# MSS_CTRL_MSS_CTRL_50D00000h register map
Vendor: Texas Instruments
Registers are 32-bit, read-write, reset values left out (the file's numbers can be read two ways) unless marked. A register's access mark holds for its fields unless they carry their own. Offsets are as the file gives them; [hi:lo] are bit positions; {n}, {i} and the like mark numbered series; 'fields as' and 'values as' point back to an identical list.

## MSS_CTRL (part 2 of 6)
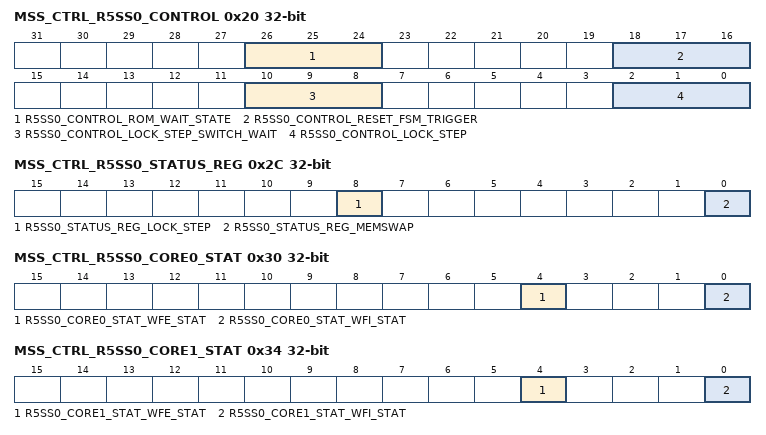
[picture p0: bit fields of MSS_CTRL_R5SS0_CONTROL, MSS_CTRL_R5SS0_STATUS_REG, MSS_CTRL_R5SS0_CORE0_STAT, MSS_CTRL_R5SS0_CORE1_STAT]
0x20 MSS_CTRL_R5SS0_CONTROL
  [26:24] R5SS0_CONTROL_ROM_WAIT_STATE — Writing 3'b111 enables a single cycle wait state with respect to CR5A_clk for rom access.This needs to be set when R5 clock is at 400MHZ and Interconnect-clk is at 200MHZ. [because it is a timing issue in this scenario]
  [18:16] R5SS0_CONTROL_RESET_FSM_TRIGGER — Write pulse bit field:Writing 3'b111 will trigger the reset FSM. Reset FSM ensures reset to R5SS and inturn ensures the latching of lock_step and also mem_swap bit
  [10:8] R5SS0_CONTROL_LOCK_STEP_SWITCH_WAIT — Writing 3'b111 ensures switch happens only after R5SS reset. Orelse it will be a immediate switch.
  [2:0] R5SS0_CONTROL_LOCK_STEP — Writing 3'b000 ensures R5 to be in Dual-Core mode. Note: The change happens after the R5SS reset assertion if corresponding R5SS_CONTROL_LOCK_STEP_SWITCH_WAIT is set. Or else the switiching to Dual-core happens on the fly.
0x24 MSS_CTRL_R5SS0_CORE0_HALT
  [2:0] R5SS0_CORE0_HALT_HALT — Writing 3'b000 will unhalt CR5A. This register should be written only once.
0x28 MSS_CTRL_R5SS0_CORE1_HALT
  [2:0] R5SS0_CORE1_HALT_HALT — Writing 3'b000 will unhalt for CR5B. This register should be written only once.
0x2C MSS_CTRL_R5SS0_STATUS_REG ro
  [8] R5SS0_STATUS_REG_LOCK_STEP — Reading1:confirms R5SS is in lockstep mode. Reading0:confirms R5SS is in Dual-core mode.
  [0] R5SS0_STATUS_REG_MEMSWAP — Reading1:confirms ROM is Eclipsed from with RAM for R5.
0x30 MSS_CTRL_R5SS0_CORE0_STAT ro
  [4] R5SS0_CORE0_STAT_WFE_STAT — WFE Status
  [0] R5SS0_CORE0_STAT_WFI_STAT — WFI Status
0x34 MSS_CTRL_R5SS0_CORE1_STAT ro
  [4] R5SS0_CORE1_STAT_WFE_STAT — WFE Status
  [0] R5SS0_CORE1_STAT_WFI_STAT — WFI Status
0x38 MSS_CTRL_R5SS0_FORCE_WFI
  [2:0] R5SS0_FORCE_WFI_CR5_WFI_OVERIDE — Writing 3'b111 will force the wfi signals of R5SS to 1
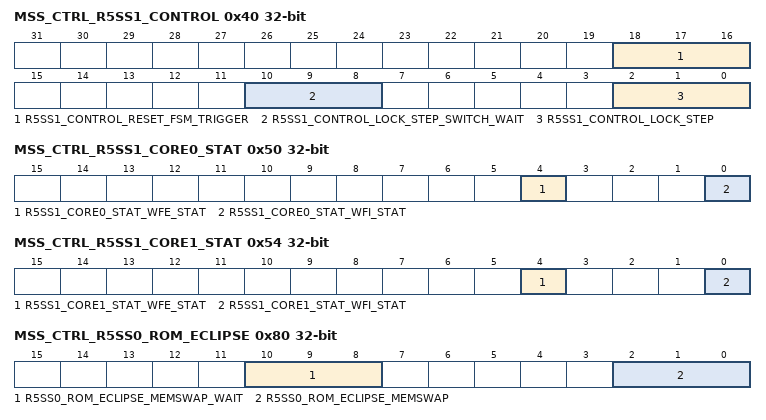
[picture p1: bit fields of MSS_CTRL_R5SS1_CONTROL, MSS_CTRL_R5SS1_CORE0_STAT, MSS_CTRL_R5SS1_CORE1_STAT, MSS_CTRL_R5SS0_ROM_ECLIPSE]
0x40 MSS_CTRL_R5SS1_CONTROL
  [18:16] R5SS1_CONTROL_RESET_FSM_TRIGGER — Write pulse bit field:Writing 3'b111 will trigger the reset FSM. Reset FSM ensures reset to R5SS and inturn ensures the latching of lock_step and also mem_swap bit
  [10:8] R5SS1_CONTROL_LOCK_STEP_SWITCH_WAIT — Writing 3'b111 ensures switch happens only after R5SS reset. Orelse it will be a immediate switch.
  [2:0] R5SS1_CONTROL_LOCK_STEP — Writing 3'b000 ensures R5 to be in Dual-Core mode. Note: The change happens after the R5SS reset assertion if corresponding R5SS_CONTROL_LOCK_STEP_SWITCH_WAIT is set. Or else the switiching to Dual-core happens on the fly.
0x44 MSS_CTRL_R5SS1_CORE0_HALT
  [2:0] R5SS1_CORE0_HALT_HALT — Writing 3'b000 will unhalt CR5A. This register should be written only once.
0x48 MSS_CTRL_R5SS1_CORE1_HALT
  [2:0] R5SS1_CORE1_HALT_HALT — Writing 3'b000 will unhalt for CR5B. This register should be written only once.
0x4C MSS_CTRL_R5SS1_STATUS_REG ro
  [8] R5SS1_STATUS_REG_LOCK_STEP — Reading1:confirms R5SS is in lockstep mode. Reading0:confirms R5SS is in Dual-core mode.
0x50 MSS_CTRL_R5SS1_CORE0_STAT ro
  [4] R5SS1_CORE0_STAT_WFE_STAT — WFE Status
  [0] R5SS1_CORE0_STAT_WFI_STAT — WFI Status
0x54 MSS_CTRL_R5SS1_CORE1_STAT ro
  [4] R5SS1_CORE1_STAT_WFE_STAT — WFE Status
  [0] R5SS1_CORE1_STAT_WFI_STAT — WFI Status
0x58 MSS_CTRL_R5SS1_FORCE_WFI
  [2:0] R5SS1_FORCE_WFI_CR5_WFI_OVERIDE — Writing 3'b111 will force the wfi signals of R5SS to 1
0x80 MSS_CTRL_R5SS0_ROM_ECLIPSE
  [10:8] R5SS0_ROM_ECLIPSE_MEMSWAP_WAIT — Writing 3'b111 ensures ROM-Eclipsing happens only after R5SS reset. Or else it will be a immediate change.
  [2:0] R5SS0_ROM_ECLIPSE_MEMSWAP — Writing 3'b111 ensures eclipsing of CR5A_ROM immediately if memswap_wait is not set. If memswap_wait is set then ROM is eclipsed after R5SS reset assertion.
0x200 MSS_CTRL_R5SS0_ATCM_MEM_INIT
  [0] R5SS0_ATCM_MEM_INIT_MEM_INIT — Write_pulse bit field:Writing 1'b1 will start initializing the ATCM banks of CR5A/B. Value in each row is initialized to 0x0C_0000_0000
0x204 MSS_CTRL_R5SS0_ATCM_MEM_INIT_DONE
  [0] R5SS0_ATCM_MEM_INIT_DONE_MEM_INIT_DONE — This field will be high once initialization of ATCM banks is finished. Writing '1' would clear the bit.
0x208 MSS_CTRL_R5SS0_ATCM_MEM_INIT_STATUS ro
  [0] R5SS0_ATCM_MEM_INIT_STATUS_MEM_STATUS — 1'b0: No initialization is happening for ATCM banks of CR5A/B1'b1: Initialization is in progress for ATCM banks of CR5A/B
0x210 MSS_CTRL_R5SS0_BTCM_MEM_INIT
  [0] R5SS0_BTCM_MEM_INIT_MEM_INIT — Write_pulse bit field:Writing 1'b1 will start initializing the B0/1TCM banks of CR5A/B
0x214 MSS_CTRL_R5SS0_BTCM_MEM_INIT_DONE
  [0] R5SS0_BTCM_MEM_INIT_DONE_MEM_INIT_DONE — This field will be high once initialization of B0/1TCM banks is finished. Writing '1' would clear the bit.
0x218 MSS_CTRL_R5SS0_BTCM_MEM_INIT_STATUS ro
  [0] R5SS0_BTCM_MEM_INIT_STATUS_MEM_STATUS — 1'b0: No initialization is happening for B0/1TCM banks of CR5A/B1'b1: Initialization is in progress for B0/1TCM banks of CR5A/B
0x220 MSS_CTRL_R5SS1_ATCM_MEM_INIT
  [0] R5SS1_ATCM_MEM_INIT_MEM_INIT — Write_pulse bit field:Writing 1'b1 will start initializing the ATCM banks of CR5A/B. Value in each row is initialized to 0x0C_0000_0000
0x224 MSS_CTRL_R5SS1_ATCM_MEM_INIT_DONE
  [0] R5SS1_ATCM_MEM_INIT_DONE_MEM_INIT_DONE — This field will be high once initialization of ATCM banks is finished. Writing '1' would clear the bit.
0x228 MSS_CTRL_R5SS1_ATCM_MEM_INIT_STATUS ro
  [0] R5SS1_ATCM_MEM_INIT_STATUS_MEM_STATUS — 1'b0: No initialization is happening for ATCM banks of CR5A/B1'b1: Initialization is in progress for ATCM banks of CR5A/B
0x230 MSS_CTRL_R5SS1_BTCM_MEM_INIT
  [0] R5SS1_BTCM_MEM_INIT_MEM_INIT — Write_pulse bit field:Writing 1'b1 will start initializing the B0/1TCM banks of CR5A/B
0x234 MSS_CTRL_R5SS1_BTCM_MEM_INIT_DONE
  [0] R5SS1_BTCM_MEM_INIT_DONE_MEM_INIT_DONE — This field will be high once initialization of B0/1TCM banks is finished. Writing '1' would clear the bit.
0x238 MSS_CTRL_R5SS1_BTCM_MEM_INIT_STATUS ro
  [0] R5SS1_BTCM_MEM_INIT_STATUS_MEM_STATUS — 1'b0: No initialization is happening for B0/1TCM banks of CR5A/B1'b1: Initialization is in progress for B0/1TCM banks of CR5A/B
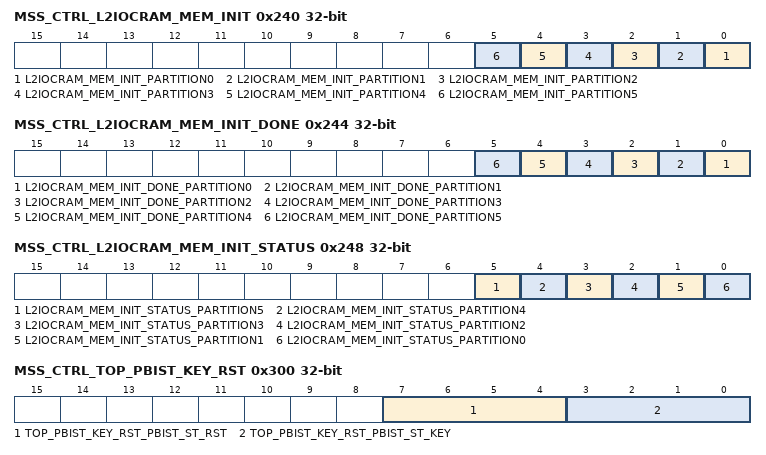
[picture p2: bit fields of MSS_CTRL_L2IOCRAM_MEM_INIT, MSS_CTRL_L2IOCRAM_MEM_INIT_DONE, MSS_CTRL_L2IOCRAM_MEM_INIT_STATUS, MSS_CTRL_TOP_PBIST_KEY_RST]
0x240 MSS_CTRL_L2IOCRAM_MEM_INIT
  [n] L2IOCRAM_MEM_INIT_PARTITION{n} (n=0..5) — Write_pulse bit field:Writing 1'b1 will start initializing the L2 Bank{n}. Value in each row is initialized to 0x0
0x244 MSS_CTRL_L2IOCRAM_MEM_INIT_DONE
  [n] L2IOCRAM_MEM_INIT_DONE_PARTITION{n} (n=0..5) — This field will be high once intialization of L2 bank{n} is finished. Writing '1' would clear the bit
0x248 MSS_CTRL_L2IOCRAM_MEM_INIT_STATUS ro
  [5] L2IOCRAM_MEM_INIT_STATUS_PARTITION5 — 1'b0: No initialization is happening for L2 bank51'b1: Initialization is in progress for L2 bank5
  [4] L2IOCRAM_MEM_INIT_STATUS_PARTITION4 — 1'b0: No initialization is happening for L2 bank41'b1: Initialization is in progress for L2 bank4
  [3] L2IOCRAM_MEM_INIT_STATUS_PARTITION3 — 1'b0: No initialization is happening for L2 bank31'b1: Initialization is in progress for L2 bank3
  [2] L2IOCRAM_MEM_INIT_STATUS_PARTITION2 — 1'b0: No initialization is happening for L2 bank2 1'b1: Initialization is in progress for L2 bank2
  [1] L2IOCRAM_MEM_INIT_STATUS_PARTITION1 — 1'b0: No initialization is happening for L2 bank11'b1: Initialization is in progress for L2 bank1
  [0] L2IOCRAM_MEM_INIT_STATUS_PARTITION0 — 1'b0: No initialization is happening for L2 bank0 1'b1: Initialization is in progress for L2 bank0
0x250 MSS_CTRL_MAILBOXRAM_MEM_INIT
  [0] MAILBOXRAM_MEM_INIT_MEM0_INIT — Write_pulse bit field:Writing 1'b1 will start initializing the MSS_MBOX. Value in each row is initialized to 0x0
0x254 MSS_CTRL_MAILBOXRAM_MEM_INIT_DONE
  [0] MAILBOXRAM_MEM_INIT_DONE_MEM0_DONE — This field will be high once intialization of MSS_MBOX is finished. Writing '1' would clear the bit
0x258 MSS_CTRL_MAILBOXRAM_MEM_INIT_STATUS ro
  [0] MAILBOXRAM_MEM_INIT_STATUS_MEM0_STATUS — 1'b0: No initialization is happening for MSS_MBOX 1'b1: Initialization is in progress for MSS_MBOX
0x260 MSS_CTRL_TPCC_MEM_INIT
  [0] TPCC_MEM_INIT_TPCC_A_MEMINIT_START — Write_pulse bit field:Writing 1'b1 will start initializing the MSS_TPCCA
0x264 MSS_CTRL_TPCC_MEM_INIT_DONE
  [0] TPCC_MEM_INIT_DONE_TPCC_A_MEMINIT_DONE — This field will be high once intialization of MSS_TPCCA is finished. Writing '1' would clear the bit
0x268 MSS_CTRL_TPCC_MEMINIT_STATUS ro
  [0] TPCC_MEMINIT_STATUS_TPCC_A_MEMINIT_STATUS — 1'b0: No initialization is happening for MSS_TPCCA1'b1: Initialization is in progress for MSS_TPCCB
0x300 MSS_CTRL_TOP_PBIST_KEY_RST
  [7:4] TOP_PBIST_KEY_RST_PBIST_ST_RST — MSS PBIST controller will be brought out of reset when value is 0xA
  [3:0] TOP_PBIST_KEY_RST_PBIST_ST_KEY — Top PBIST Selftest Key. Valid value is 0x5
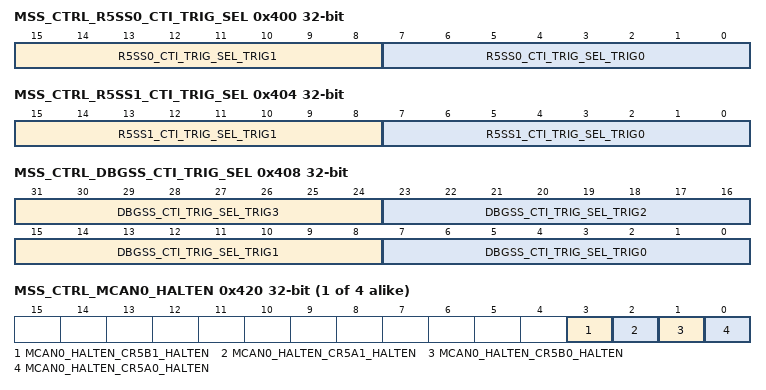
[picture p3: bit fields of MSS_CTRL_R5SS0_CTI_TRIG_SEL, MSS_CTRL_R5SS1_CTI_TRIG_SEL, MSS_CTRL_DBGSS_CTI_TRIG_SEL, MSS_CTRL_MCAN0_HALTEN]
0x400 MSS_CTRL_R5SS0_CTI_TRIG_SEL
  [15:8] R5SS0_CTI_TRIG_SEL_TRIG1 — Used for selecting the trigger source for 1st trigger of MSS_R5SS
  [7:0] R5SS0_CTI_TRIG_SEL_TRIG0 — Used for selecting the trigger source for 0th trigger of MSS_R5SS
0x404 MSS_CTRL_R5SS1_CTI_TRIG_SEL
  [15:8] R5SS1_CTI_TRIG_SEL_TRIG1 — Used for selecting the trigger source for 1st trigger of MSS_R5SS
  [7:0] R5SS1_CTI_TRIG_SEL_TRIG0 — Used for selecting the trigger source for 0th trigger of MSS_R5SS
0x408 MSS_CTRL_DBGSS_CTI_TRIG_SEL
  [31:24] DBGSS_CTI_TRIG_SEL_TRIG3 — Used for selecting the trigger source for 3rd trigger of ONE_MCU_CTI
  [23:16] DBGSS_CTI_TRIG_SEL_TRIG2 — Used for selecting the trigger source for 2nd trigger of ONE_MCU_CTI
  [15:8] DBGSS_CTI_TRIG_SEL_TRIG1 — Used for selecting the trigger source for 1st trigger of ONE_MCU_CTI
  [7:0] DBGSS_CTI_TRIG_SEL_TRIG0 — Used for selecting the trigger source for 0th trigger of ONE_MCU_CTI
{0x420+4i} MSS_CTRL_MCAN{i}_HALTEN (i=0..3)
  [3] MCAN{i}_HALTEN_CR5B1_HALTEN — 1'b0: IP Halt disabled with corresponding CPU halt1'b1: IP Halt enabled with corresponding CPU halt
  [2] MCAN{i}_HALTEN_CR5A1_HALTEN — 1'b0: IP Halt disabled with corresponding CPU halt1'b1: IP Halt enabled with corresponding CPU halt
  [1] MCAN{i}_HALTEN_CR5B0_HALTEN — 1'b0: IP Halt disabled with corresponding CPU halt1'b1: IP Halt enabled with corresponding CPU halt
  [0] MCAN{i}_HALTEN_CR5A0_HALTEN — 1'b0: IP Halt disabled with corresponding CPU halt1'b1: IP Halt enabled with corresponding CPU halt
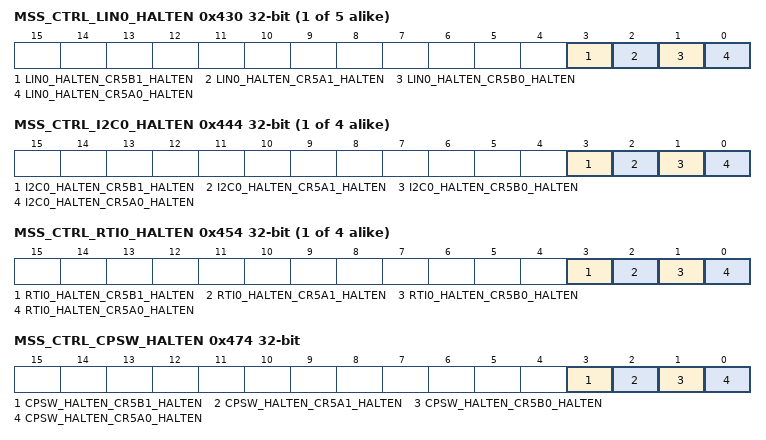
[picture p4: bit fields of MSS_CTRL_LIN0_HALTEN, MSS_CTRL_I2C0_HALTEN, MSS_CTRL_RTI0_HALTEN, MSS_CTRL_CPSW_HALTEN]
{0x430+4i} MSS_CTRL_LIN{i}_HALTEN (i=0..4)
  [3] LIN{i}_HALTEN_CR5B1_HALTEN — 1'b0: IP Halt disabled with corresponding CPU halt1'b1: IP Halt enabled with corresponding CPU halt
  [2] LIN{i}_HALTEN_CR5A1_HALTEN — 1'b0: IP Halt disabled with corresponding CPU halt1'b1: IP Halt enabled with corresponding CPU halt
  [1] LIN{i}_HALTEN_CR5B0_HALTEN — 1'b0: IP Halt disabled with corresponding CPU halt1'b1: IP Halt enabled with corresponding CPU halt
  [0] LIN{i}_HALTEN_CR5A0_HALTEN — 1'b0: IP Halt disabled with corresponding CPU halt1'b1: IP Halt enabled with corresponding CPU halt
{0x444+4i} MSS_CTRL_I2C{i}_HALTEN (i=0..3)
  [3] I2C{i}_HALTEN_CR5B1_HALTEN — 1'b0: IP Halt disabled with corresponding CPU halt1'b1: IP Halt enabled with corresponding CPU halt
  [2] I2C{i}_HALTEN_CR5A1_HALTEN — 1'b0: IP Halt disabled with corresponding CPU halt1'b1: IP Halt enabled with corresponding CPU halt
  [1] I2C{i}_HALTEN_CR5B0_HALTEN — 1'b0: IP Halt disabled with corresponding CPU halt1'b1: IP Halt enabled with corresponding CPU halt
  [0] I2C{i}_HALTEN_CR5A0_HALTEN — 1'b0: IP Halt disabled with corresponding CPU halt1'b1: IP Halt enabled with corresponding CPU halt
{0x454+4i} MSS_CTRL_RTI{i}_HALTEN (i=0..3)
  [3] RTI{i}_HALTEN_CR5B1_HALTEN — 1'b0: IP Halt disabled with corresponding CPU halt1'b1: IP Halt enabled with corresponding CPU halt
  [2] RTI{i}_HALTEN_CR5A1_HALTEN — 1'b0: IP Halt disabled with corresponding CPU halt1'b1: IP Halt enabled with corresponding CPU halt
  [1] RTI{i}_HALTEN_CR5B0_HALTEN — 1'b0: IP Halt disabled with corresponding CPU halt1'b1: IP Halt enabled with corresponding CPU halt
  [0] RTI{i}_HALTEN_CR5A0_HALTEN — 1'b0: IP Halt disabled with corresponding CPU halt1'b1: IP Halt enabled with corresponding CPU halt
0x474 MSS_CTRL_CPSW_HALTEN
  [3] CPSW_HALTEN_CR5B1_HALTEN — 1'b0: IP Halt disabled with corresponding CPU halt1'b1: IP Halt enabled with corresponding CPU halt
  [2] CPSW_HALTEN_CR5A1_HALTEN — 1'b0: IP Halt disabled with corresponding CPU halt1'b1: IP Halt enabled with corresponding CPU halt
  [1] CPSW_HALTEN_CR5B0_HALTEN — 1'b0: IP Halt disabled with corresponding CPU halt1'b1: IP Halt enabled with corresponding CPU halt
  [0] CPSW_HALTEN_CR5A0_HALTEN — 1'b0: IP Halt disabled with corresponding CPU halt1'b1: IP Halt enabled with corresponding CPU halt
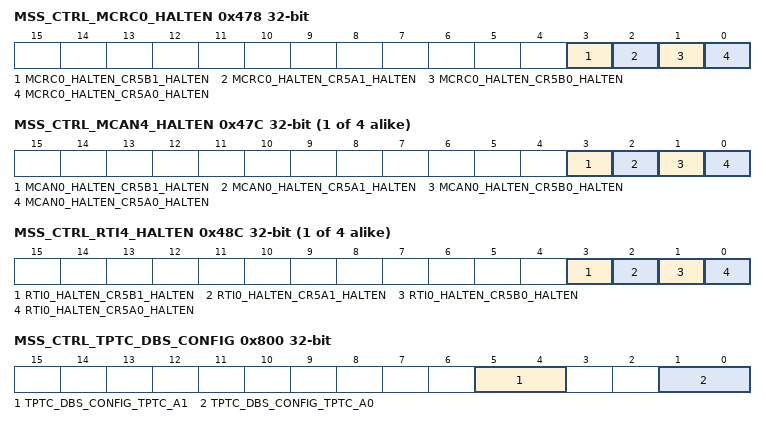
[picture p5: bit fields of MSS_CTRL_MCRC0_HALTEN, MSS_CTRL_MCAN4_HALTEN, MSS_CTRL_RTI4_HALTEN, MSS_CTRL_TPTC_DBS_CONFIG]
0x478 MSS_CTRL_MCRC0_HALTEN
  [3] MCRC0_HALTEN_CR5B1_HALTEN — 1'b0: IP Halt disabled with corresponding CPU halt1'b1: IP Halt enabled with corresponding CPU halt
  [2] MCRC0_HALTEN_CR5A1_HALTEN — 1'b0: IP Halt disabled with corresponding CPU halt1'b1: IP Halt enabled with corresponding CPU halt
  [1] MCRC0_HALTEN_CR5B0_HALTEN — 1'b0: IP Halt disabled with corresponding CPU halt1'b1: IP Halt enabled with corresponding CPU halt
  [0] MCRC0_HALTEN_CR5A0_HALTEN — 1'b0: IP Halt disabled with corresponding CPU halt1'b1: IP Halt enabled with corresponding CPU halt
{0x46C+4i} MSS_CTRL_MCAN{i}_HALTEN (i=4..7)
  fields as MSS_CTRL_MCAN0_HALTEN
{0x47C+4i} MSS_CTRL_RTI{i}_HALTEN (i=4..7)
  fields as MSS_CTRL_RTI0_HALTEN
0x800 MSS_CTRL_TPTC_DBS_CONFIG
  [5:4] TPTC_DBS_CONFIG_TPTC_A1 — DBS [default burst size] tieoff value for TPTC A1. DBS tieoff defines optimally sized cmd.Both the read and write controller will always issue commands that are less than or equal to the DBS tieoff value. This will typically be on the order of 4 or 8 dataphases worth of data. DBS must always be tied off to no larger than half of the Channel FIFO size. Set DBS to -2'b00 = 16 byte 2'b01 = 32 byte 2'b10 = 64 byte 2'b11 = 128 byte
  [1:0] TPTC_DBS_CONFIG_TPTC_A0 — DBS [default burst size] tieoff value for TPTC A0. DBS tieoff defines optimally sized cmd.Both the read and write controller will always issue commands that are less than or equal to the DBS tieoff value. This will typically be on the order of 4 or 8 dataphases worth of data. DBS must always be tied off to no larger than half of the Channel FIFO size. Set DBS to -2'b00 = 16 byte 2'b01 = 32 byte 2'b10 = 64 byte 2'b11 = 128 byte
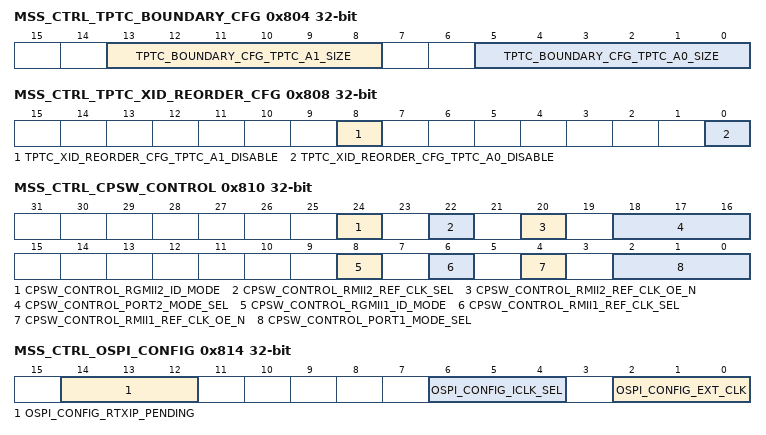
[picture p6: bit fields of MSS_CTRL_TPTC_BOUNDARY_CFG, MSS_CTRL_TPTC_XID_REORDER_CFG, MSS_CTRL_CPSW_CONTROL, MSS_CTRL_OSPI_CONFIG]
0x804 MSS_CTRL_TPTC_BOUNDARY_CFG
  [13:8] TPTC_BOUNDARY_CFG_TPTC_A1_SIZE — 6 bit signal used for deciding the boundary crossing size for CID-RID-SID reordering of MSS_TPTC_A1Example: Writing 6'd19 decidies boundary to be 2^19 i.e. 512 KB
  [5:0] TPTC_BOUNDARY_CFG_TPTC_A0_SIZE — 6 bit signal used for deciding the boundary crossing size for CID-RID-SID reordering of MSS_TPTC_A0Example: Writing 6'd19 decidies boundary to be 2^19 i.e. 512 KB
0x808 MSS_CTRL_TPTC_XID_REORDER_CFG
  [8] TPTC_XID_REORDER_CFG_TPTC_A1_DISABLE — Writing 1'b1 will disable the CID-RID-SID reodering feature for MSS_TPTC_A1
  [0] TPTC_XID_REORDER_CFG_TPTC_A0_DISABLE — Writing 1'b1 will disable the CID-RID-SID reodering feature for MSS_TPTC_A0
0x810 MSS_CTRL_CPSW_CONTROL
  [24] CPSW_CONTROL_RGMII2_ID_MODE — Internal delay mode for port 2. Only for TX1'b0 ID mode is disabled1'b1 ID mode is enabled
  [22] CPSW_CONTROL_RMII2_REF_CLK_SEL — To select the rmii_ref_clk loopback mux output either from PAD or from MSS_RCM. Write 1'b0 to get clock will be from IO pad[pad loopback]. Write 1'b1 to get clock from internal loopback.
  [20] CPSW_CONTROL_RMII2_REF_CLK_OE_N — RMII_REF_CLK IO Output enable control1'b0: Output enable1'b1: Output Disable
  [18:16] CPSW_CONTROL_PORT2_MODE_SEL — Port 2 Interface 3'b000 = MII3'b001 = RMII3'b010 = RGMII011 - 111 = Not Supported
  [8] CPSW_CONTROL_RGMII1_ID_MODE — Internal delay mode for port 1. Only for TX1'b0 ID mode is disabled1'b1 ID mode is enabled
  [6] CPSW_CONTROL_RMII1_REF_CLK_SEL — To select the rmii_ref_clk loopback mux output either from PAD or from MSS_RCM. Write 1'b0 to get clock will be from IO pad[pad loopback]. Write 1'b1 to get clock from internal source
  [4] CPSW_CONTROL_RMII1_REF_CLK_OE_N — RMII_REF_CLK IO Output enable control1'b0: Output enable1'b1: Output Disable
  [2:0] CPSW_CONTROL_PORT1_MODE_SEL — Port 1 Interface 3'b000 = MII3'b001 = RMII3'b010 = RGMII011 - 111 = Not Supported
0x814 MSS_CTRL_OSPI_CONFIG
  [14:12] OSPI_CONFIG_RTXIP_PENDING — Real time xip indication for OSPIWrite 3'b111 for real time xip is pendingWrite 3'b000 for real time xip is doneconfiguration changes must be done when FSS is idle/not configured/no transactions
  [6:4] OSPI_CONFIG_ICLK_SEL — Write 3'b111 to switch to loopback clock as OSPI input IO clockWrite 3'b000 to switch to OSPI DQS as OSPI input IO clockconfiguration changes must be done when FSS is idle/not configured/no transactions
  [2:0] OSPI_CONFIG_EXT_CLK — Write 3'b111 to external clock as OSPI baud clock source - needed for DFT IO char.
0x818 MSS_CTRL_PRU_ICSS_IDLE_CONTROL
  [0] PRU_ICSS_IDLE_CONTROL_NOGATE — Writing 1'b0 will enable local auto-clock gating [lower power] at IP level with increase in access/functional latency. Following IPs are controlled with this signalICSSM
0x81C MSS_CTRL_PRU_ICSS_PRU0_GPI_SEL
  [29:0] PRU_ICSS_PRU0_GPI_SEL_SEL — GPI or PWMXBAR select for ICSM Port03'b000 GPI3'111 PWMXBAR
0x820 MSS_CTRL_PRU_ICSS_PRU1_GPI_SEL
  [29:0] PRU_ICSS_PRU1_GPI_SEL_SEL — GPI or PWMXBAR select for ICSM Port03'b000 GPI3'111 PWMXBAR
0x824 MSS_CTRL_PRU_ICSS_PRU0_GPIO_OUT_CTRL
  [29:0] PRU_ICSS_PRU0_GPIO_OUT_CTRL_OUTDISABLE — GPO output disable for ICSSM Port 0 IO. Disable output for using the pin as input. Each Bit maps to the corresponding bit in the IO3'b000 Output Enable3'111 Output Disable
0x828 MSS_CTRL_PRU_ICSS_PRU1_GPIO_OUT_CTRL
  [29:0] PRU_ICSS_PRU1_GPIO_OUT_CTRL_OUTDISABLE — GPO output disable for ICSSM Port 1 IO. Disable output for using the pin as input. Each Bit maps to the corresponding bit in the IO3'b000 Output Enable3'111 Output Disable
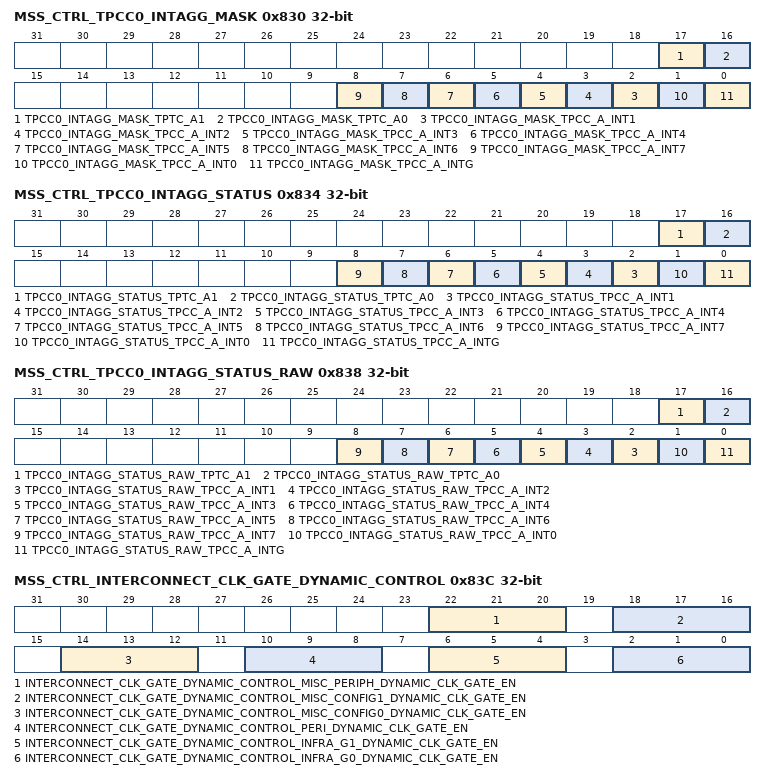
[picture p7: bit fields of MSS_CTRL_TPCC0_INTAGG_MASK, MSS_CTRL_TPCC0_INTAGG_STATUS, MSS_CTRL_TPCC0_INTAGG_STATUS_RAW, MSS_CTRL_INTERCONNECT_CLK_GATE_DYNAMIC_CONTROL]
0x830 MSS_CTRL_TPCC0_INTAGG_MASK
  [17] TPCC0_INTAGG_MASK_TPTC_A1 — Mask Interrupt from TPTC A1 to aggregated Interrupt MSS_TPCC_A_INTAGG1'b1 : Interrupt is Masked1'b0 : Interrupt is Unmasked
  [16] TPCC0_INTAGG_MASK_TPTC_A0 — Mask Interrupt from TPTC A0 to aggregated Interrupt MSS_TPCC_A_INTAGG1'b1 : Interrupt is Masked1'b0 : Interrupt is Unmasked
  [n+1] TPCC0_INTAGG_MASK_TPCC_A_INT{n} (n=1..7) — Mask Interrupt from MSS_TPCC_A to aggregated Interrupt MSS_TPCC_A_INTAGG1'b1 : Interrupt is Masked1'b0 : Interrupt is Unmasked
  [1] TPCC0_INTAGG_MASK_TPCC_A_INT0 — Mask Interrupt from TPCC A to aggregated Interrupt MSS_TPCC_A_INTAGG1'b1 : Interrupt is Masked1'b0 : Interrupt is Unmasked
  [0] TPCC0_INTAGG_MASK_TPCC_A_INTG — Mask Interrupt from MSS_TPCC_A to aggregated Interrupt MSS_TPCC_A_INTAGG1'b1 : Interrupt is Masked1'b0 : Interrupt is Unmasked
0x834 MSS_CTRL_TPCC0_INTAGG_STATUS
  [17] TPCC0_INTAGG_STATUS_TPTC_A1 — Status of Interrupt from TPTC A1. Set only if Interupt is unmasked in TPCC0_INTAGG_MASKWrie 0x1 to clear this interrupt.
  [16] TPCC0_INTAGG_STATUS_TPTC_A0 — Status of Interrupt from TPTC A0. Set only if Interupt is unmasked in TPCC0_INTAGG_MASKWrie 0x1 to clear this interrupt.
  [n+1] TPCC0_INTAGG_STATUS_TPCC_A_INT{n} (n=1..7) — Status of Interrupt from MSS_TPCC_A. Set only if Interupt is unmasked in TPCC0_INTAGG_MASKWrie 0x1 to clear this interrupt.
  [1] TPCC0_INTAGG_STATUS_TPCC_A_INT0 — Status of Interrupt from TPCC A Set only if Interupt is unmasked in TPCC0_INTAGG_MASKWrie 0x1 to clear this interrupt.
  [0] TPCC0_INTAGG_STATUS_TPCC_A_INTG — Status of Interrupt from MSS_TPCC_A. Set only if Interupt is unmasked in TPCC0_INTAGG_MASKWrie 0x1 to clear this interrupt.
0x838 MSS_CTRL_TPCC0_INTAGG_STATUS_RAW
  [17] TPCC0_INTAGG_STATUS_RAW_TPTC_A1 — Raw Status of Interrupt from TPTC A1. Set irrespective if the Interupt is masked or unmasked in TPCC0_INTAGG_MASK
  [16] TPCC0_INTAGG_STATUS_RAW_TPTC_A0 — Raw Status of Interrupt from TPTC A0. Set irrespective if the Interupt is masked or unmasked in TPCC0_INTAGG_MASK
  [n+1] TPCC0_INTAGG_STATUS_RAW_TPCC_A_INT{n} (n=1..7) — Raw Status of Interrupt from MSS_TPCC_A. Set irrespective if the Interupt is masked or unmasked in MSS_TPCC_C_INTAGG_MASK
  [1] TPCC0_INTAGG_STATUS_RAW_TPCC_A_INT0 — Raw Status of Interrupt from TPCC A. Set irrespective if the Interupt is masked or unmasked in TPCC0_INTAGG_MASK
  [0] TPCC0_INTAGG_STATUS_RAW_TPCC_A_INTG — Raw Status of Interrupt from MSS_TPCC_A. Set irrespective if the Interupt is masked or unmasked in MSS_TPCC_C_INTAGG_MASK
0x83C MSS_CTRL_INTERCONNECT_CLK_GATE_DYNAMIC_CONTROL
  [22:20] INTERCONNECT_CLK_GATE_DYNAMIC_CONTROL_MISC_PERIPH_DYNAMIC_CLK_GATE_EN — dynamic clock gate feature enable. Multibit writeWrite 0x111 to enable Write 0x000 to disable2 extra clock latency for the first access after the clock is gated and SCRP_PERI is not gated
  [18:16] INTERCONNECT_CLK_GATE_DYNAMIC_CONTROL_MISC_CONFIG1_DYNAMIC_CLK_GATE_EN — dynamic clock gate feature enable. Multibit writeWrite 0x111 to enable Write 0x000 to disable2 extra clock latency for the first access after the clock is gated and SCRP_PERI is not gated
  [14:12] INTERCONNECT_CLK_GATE_DYNAMIC_CONTROL_MISC_CONFIG0_DYNAMIC_CLK_GATE_EN — dynamic clock gate feature enable. Multibit writeWrite 0x111 to enable Write 0x000 to disable2 extra clock latency for the first access after the clock is gated and SCRP_PERI is not gated
  [10:8] INTERCONNECT_CLK_GATE_DYNAMIC_CONTROL_PERI_DYNAMIC_CLK_GATE_EN — dynamic clock gate feature enable. Multibit writeWrite 0x111 to enable Write 0x000 to disable2 extra clock latency for the first access after the clock is gated and SCRP_PERI is not gated
  [6:4] INTERCONNECT_CLK_GATE_DYNAMIC_CONTROL_INFRA_G1_DYNAMIC_CLK_GATE_EN — dynamic clock gate feature enable. Multibit writeWrite 0x111 to enable Write 0x000 to disable2 extra clock latency for the first access after the clock is gated and SCRP_PERI is not gated4 extra clock latency for the first access after the clock is gated and SCRP_PERI is gated
  [2:0] INTERCONNECT_CLK_GATE_DYNAMIC_CONTROL_INFRA_G0_DYNAMIC_CLK_GATE_EN — dynamic clock gate feature enable. Multibit writeWrite 0x111 to enable Write 0x000 to disable2 extra clock latency for the first access after the clock is gated and SCRP_PERI is not gated4 extra clock latency for the first access after the clock is gated and SCRP_PERI is gated
0x840 MSS_CTRL_OSPI_BOOT_CONFIG_MASK
  [19:0] OSPI_BOOT_CONFIG_MASK_BOOT_SIZE — OSPI boot size registerconfiguration changes must be done when FSS is idle/not configured/no transactions
0x844 MSS_CTRL_OSPI_BOOT_CONFIG_SEG
  [19:0] OSPI_BOOT_CONFIG_SEG_BOOT_SEG — OSPI segment selector for programmed boot sizeconfiguration changes must be done when FSS is idle/not configured/no transactions
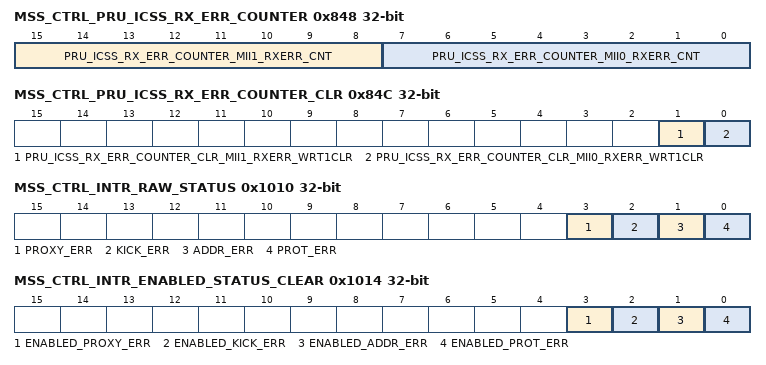
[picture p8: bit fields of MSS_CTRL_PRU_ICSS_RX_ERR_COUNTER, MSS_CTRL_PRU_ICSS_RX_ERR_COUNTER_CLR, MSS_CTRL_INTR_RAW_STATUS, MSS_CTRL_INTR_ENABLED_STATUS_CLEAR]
0x848 MSS_CTRL_PRU_ICSS_RX_ERR_COUNTER ro
  [15:8] PRU_ICSS_RX_ERR_COUNTER_MII1_RXERR_CNT — Counts the error in MII1_RX_CLK
  [7:0] PRU_ICSS_RX_ERR_COUNTER_MII0_RXERR_CNT — Counts the error in MII0_RX_CLK
0x84C MSS_CTRL_PRU_ICSS_RX_ERR_COUNTER_CLR
  [1] PRU_ICSS_RX_ERR_COUNTER_CLR_MII1_RXERR_WRT1CLR — Clears the Counter which counts the error in MII1_RX_CLK1'b0: Inactive clear1'b1: Clears the counter
  [0] PRU_ICSS_RX_ERR_COUNTER_CLR_MII0_RXERR_WRT1CLR — Clears the Counter which counts the error in MII0_RX_CLK1'b0: Inactive clear1'b1: Clears the counter
0x1008 MSS_CTRL_LOCK0_KICK0 — - KICK0 component.
  [31:0] LOCK0_KICK0 — - KICK0 component
0x100C MSS_CTRL_LOCK0_KICK1 — - KICK1 component.
  [31:0] LOCK0_KICK1 — - KICK1 component
0x1010 MSS_CTRL_INTR_RAW_STATUS access not given — Interrupt Raw Status/Set Register.
  [3] PROXY_ERR — Proxy0 access violation error. Raw status is read. Write a 1 to set the status. Writing a 0 has no effect. (access R/W1TS)
  [2] KICK_ERR — Kick access violation error. Raw status is read. Write a 1 to set the status. Writing a 0 has no effect. (access R/W1TS)
  [1] ADDR_ERR — Addressing violation error. Raw status is read. Write a 1 to set the status. Writing a 0 has no effect. (access R/W1TS)
  [0] PROT_ERR — Protection violation error. Raw status is read. Write a 1 to set the status. Writing a 0 has no effect. (access R/W1TS)
0x1014 MSS_CTRL_INTR_ENABLED_STATUS_CLEAR access not given — Interrupt Enabled Status/Clear register.
  [3] ENABLED_PROXY_ERR — Proxy0 access violation error. Enabled status is read. Write a 1 to clear the status. Writing a 0 has no effect. (access R/W1TC)
  [2] ENABLED_KICK_ERR — Kick access violation error. Enabled status is read. Write a 1 to clear the status. Writing a 0 has no effect. (access R/W1TC)
  [1] ENABLED_ADDR_ERR — Addressing violation error. Enabled status is read. Write a 1 to clear the status. Writing a 0 has no effect. (access R/W1TC)
  [0] ENABLED_PROT_ERR — Protection violation error. Enabled status is read. Write a 1 to clear the status. Writing a 0 has no effect. (access R/W1TC)
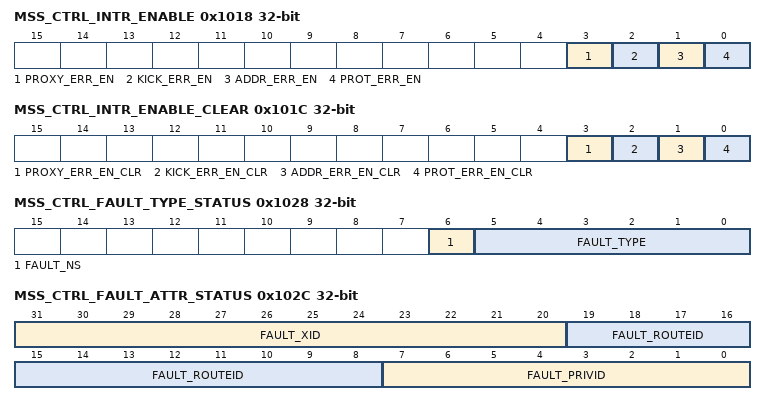
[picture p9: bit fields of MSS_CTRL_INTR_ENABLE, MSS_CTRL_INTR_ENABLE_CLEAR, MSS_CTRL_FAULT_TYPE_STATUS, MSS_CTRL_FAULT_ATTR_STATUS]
0x1018 MSS_CTRL_INTR_ENABLE access not given — Interrupt Enable register.
  [3] PROXY_ERR_EN — Proxy0 access violation error enable. Write a 1 to set the enable. Writing a 0 has no effect. (access R/W1TS)
  [2] KICK_ERR_EN — Kick access violation error enable. Write a 1 to set the enable. Writing a 0 has no effect. (access R/W1TS)
  [1] ADDR_ERR_EN — Addressing violation error enable. Write a 1 to set the enable. Writing a 0 has no effect. (access R/W1TS)
  [0] PROT_ERR_EN — Protection violation error enable. Write a 1 to set the enable. Writing a 0 has no effect. (access R/W1TS)
0x101C MSS_CTRL_INTR_ENABLE_CLEAR access not given — Interrupt Enable Clear register.
  [3] PROXY_ERR_EN_CLR — Proxy0 access violation error enable clear. Write a 1 to clear the enable. Writing a 0 has no effect. (access R/W1TC)
  [2] KICK_ERR_EN_CLR — Kick access violation error enable clear. Write a 1 to clear the enable. Writing a 0 has no effect. (access R/W1TC)
  [1] ADDR_ERR_EN_CLR — Addressing violation error enable clear. Write a 1 to clear the enable. Writing a 0 has no effect. (access R/W1TC)
  [0] PROT_ERR_EN_CLR — Protection violation error enable clear. Write a 1 to clear the enable. Writing a 0 has no effect. (access R/W1TC)
0x1020 MSS_CTRL_EOI — EOI register.
  [7:0] EOI_VECTOR — EOI vector value. Write this with interrupt distribution value in the chip.
0x1024 MSS_CTRL_FAULT_ADDRESS ro — Fault Address register.
  [31:0] FAULT_ADDR — Fault Address.
0x1028 MSS_CTRL_FAULT_TYPE_STATUS ro — Fault Type Status register.
  [6] FAULT_NS — Non-secure access.
  [5:0] FAULT_TYPE — Fault Type 10_0000 = Supervisor read fault - priv = 1 dir = 1 dtype != 1 01_0000 = Supervisor write fault - priv = 1 dir = 0 00_1000 = Supervisor execute fault - priv = 1 dir = 1 dtype = 1 00_0100 = User read fault - priv = 0 dir = 1 dtype = 1 00_0010 = User write fault - priv = 0 dir = 0 00_0001 = User execute fault - priv = 0 dir = 1 dtype = 1 00_0000 = No fault
0x102C MSS_CTRL_FAULT_ATTR_STATUS ro — Fault Attribute Status register.
  [31:20] FAULT_XID — XID.
  [19:8] FAULT_ROUTEID — Route ID.
  [7:0] FAULT_PRIVID — Privilege ID.
0x1030 MSS_CTRL_FAULT_CLEAR wo — Fault Clear register.
  [0] FAULT_CLR — Fault clear. Writing a 1 clears the current fault. Writing a 0 has no effect.
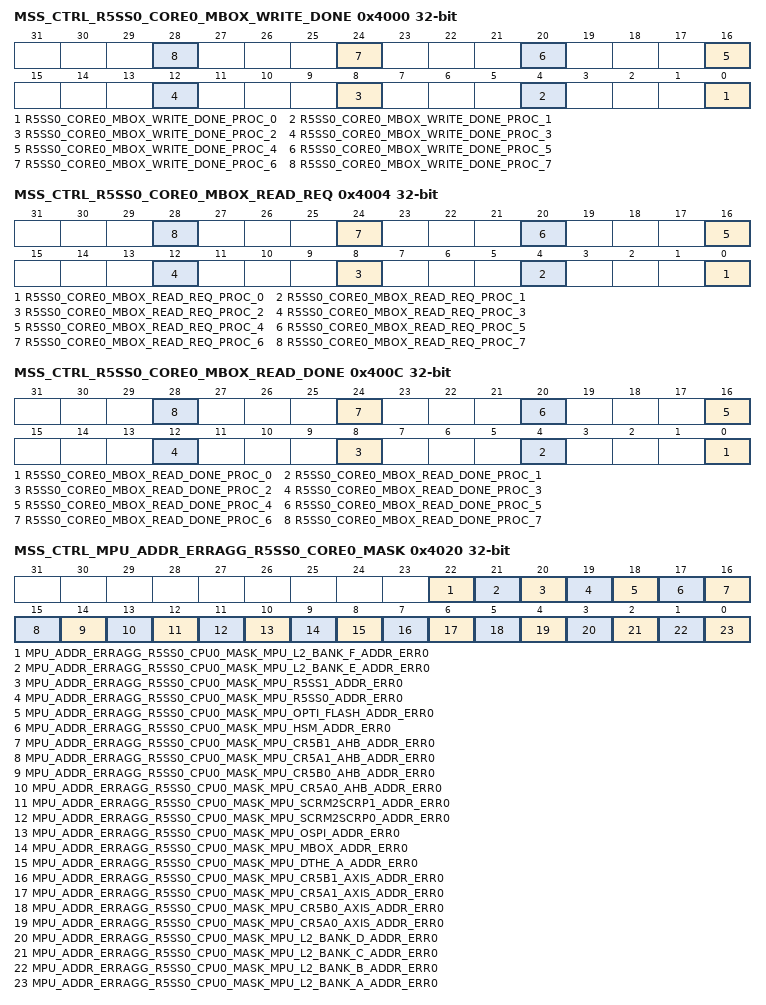
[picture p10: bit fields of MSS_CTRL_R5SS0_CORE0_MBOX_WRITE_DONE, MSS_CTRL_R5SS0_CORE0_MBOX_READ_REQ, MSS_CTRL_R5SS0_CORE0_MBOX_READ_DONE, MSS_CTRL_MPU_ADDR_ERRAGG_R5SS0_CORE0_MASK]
0x4000 MSS_CTRL_R5SS0_CORE0_MBOX_WRITE_DONE
  [4n] R5SS0_CORE0_MBOX_WRITE_DONE_PROC_{n} (n=0..7) — Write pulse bit field:This register should be written once finishing Writing into the mailbox memory of processor {n}
0x4004 MSS_CTRL_R5SS0_CORE0_MBOX_READ_REQ
  [4n] R5SS0_CORE0_MBOX_READ_REQ_PROC_{n} (n=0..7) — This is request from processor {n} to mss_cr5a. Requesting it to read from mailbox.
0x4008 MSS_CTRL_R5SS0_CORE0_MBOX_READ_DONE_ACK
  [7:0] R5SS0_CORE0_MBOX_READ_DONE_ACK_PROC — Write pulse bit field:For bits 0 to7:Wrting1'b1 : Generates pulse interrupt to corresponding proc from MSS_CR5
0x400C MSS_CTRL_R5SS0_CORE0_MBOX_READ_DONE
  [4n] R5SS0_CORE0_MBOX_READ_DONE_PROC_{n} (n=0..7) — This register should be written once finishing Reading from proc{n}'s mailbox written by CR5A
0x4010 MSS_CTRL_R5SS0_CORE0_SW_INT
  [0] R5SS0_CORE0_SW_INT_PULSE — Write_pulse bit field:Writing 1'b1 to each bit will trigger MSS_SW_INT respectively to CR5A/B.
0x4020 MSS_CTRL_MPU_ADDR_ERRAGG_R5SS0_CORE0_MASK
  [22] MPU_ADDR_ERRAGG_R5SS0_CPU0_MASK_MPU_L2_BANK_F_ADDR_ERR0 — Mask Error from MPU_ADDR_INTR to aggregated Error MPU_ADDR_INTR_ERRAGG1'b1 : Error is Masked1'b0 : Error is Unmasked
  [21] MPU_ADDR_ERRAGG_R5SS0_CPU0_MASK_MPU_L2_BANK_E_ADDR_ERR0 — Mask Error from MPU_ADDR_INTR to aggregated Error MPU_ADDR_INTR_ERRAGG1'b1 : Error is Masked1'b0 : Error is Unmasked
  [20] MPU_ADDR_ERRAGG_R5SS0_CPU0_MASK_MPU_R5SS1_ADDR_ERR0 — Mask Error from MPU_ADDR_INTR to aggregated Error MPU_ADDR_INTR_ERRAGG1'b1 : Error is Masked1'b0 : Error is Unmasked
  [19] MPU_ADDR_ERRAGG_R5SS0_CPU0_MASK_MPU_R5SS0_ADDR_ERR0 — Mask Error from MPU_ADDR_INTR to aggregated Error MPU_ADDR_INTR_ERRAGG1'b1 : Error is Masked1'b0 : Error is Unmasked
  [18] MPU_ADDR_ERRAGG_R5SS0_CPU0_MASK_MPU_OPTI_FLASH_ADDR_ERR0 — Mask Error from MPU_ADDR_INTR to aggregated Error MPU_ADDR_INTR_ERRAGG1'b1 : Error is Masked1'b0 : Error is Unmasked
  [17] MPU_ADDR_ERRAGG_R5SS0_CPU0_MASK_MPU_HSM_ADDR_ERR0 — Mask Error from MPU_ADDR_INTR to aggregated Error MPU_ADDR_INTR_ERRAGG1'b1 : Error is Masked1'b0 : Error is Unmasked
  [16] MPU_ADDR_ERRAGG_R5SS0_CPU0_MASK_MPU_CR5B1_AHB_ADDR_ERR0 — Mask Error from MPU_ADDR_INTR to aggregated Error MPU_ADDR_INTR_ERRAGG1'b1 : Error is Masked1'b0 : Error is Unmasked
  [15] MPU_ADDR_ERRAGG_R5SS0_CPU0_MASK_MPU_CR5A1_AHB_ADDR_ERR0 — Mask Error from MPU_ADDR_INTR to aggregated Error MPU_ADDR_INTR_ERRAGG1'b1 : Error is Masked1'b0 : Error is Unmasked
  [14] MPU_ADDR_ERRAGG_R5SS0_CPU0_MASK_MPU_CR5B0_AHB_ADDR_ERR0 — Mask Error from MPU_ADDR_INTR to aggregated Error MPU_ADDR_INTR_ERRAGG1'b1 : Error is Masked1'b0 : Error is Unmasked
  [13] MPU_ADDR_ERRAGG_R5SS0_CPU0_MASK_MPU_CR5A0_AHB_ADDR_ERR0 — Mask Error from MPU_ADDR_INTR to aggregated Error MPU_ADDR_INTR_ERRAGG1'b1 : Error is Masked1'b0 : Error is Unmasked
  [12] MPU_ADDR_ERRAGG_R5SS0_CPU0_MASK_MPU_SCRM2SCRP1_ADDR_ERR0 — Mask Error from MPU_ADDR_INTR to aggregated Error MPU_ADDR_INTR_ERRAGG1'b1 : Error is Masked1'b0 : Error is Unmasked
  [11] MPU_ADDR_ERRAGG_R5SS0_CPU0_MASK_MPU_SCRM2SCRP0_ADDR_ERR0 — Mask Error from MPU_ADDR_INTR to aggregated Error MPU_ADDR_INTR_ERRAGG1'b1 : Error is Masked1'b0 : Error is Unmasked
  [10] MPU_ADDR_ERRAGG_R5SS0_CPU0_MASK_MPU_OSPI_ADDR_ERR0 — Mask Error from MPU_ADDR_INTR to aggregated Error MPU_ADDR_INTR_ERRAGG1'b1 : Error is Masked1'b0 : Error is Unmasked
  [9] MPU_ADDR_ERRAGG_R5SS0_CPU0_MASK_MPU_MBOX_ADDR_ERR0 — Mask Error from MPU_ADDR_INTR to aggregated Error MPU_ADDR_INTR_ERRAGG1'b1 : Error is Masked1'b0 : Error is Unmasked
  [8] MPU_ADDR_ERRAGG_R5SS0_CPU0_MASK_MPU_DTHE_A_ADDR_ERR0 — Mask Error from MPU_ADDR_INTR to aggregated Error MPU_ADDR_INTR_ERRAGG1'b1 : Error is Masked1'b0 : Error is Unmasked
  [7] MPU_ADDR_ERRAGG_R5SS0_CPU0_MASK_MPU_CR5B1_AXIS_ADDR_ERR0 — Mask Error from MPU_ADDR_INTR to aggregated Error MPU_ADDR_INTR_ERRAGG1'b1 : Error is Masked1'b0 : Error is Unmasked
  [6] MPU_ADDR_ERRAGG_R5SS0_CPU0_MASK_MPU_CR5A1_AXIS_ADDR_ERR0 — Mask Error from MPU_ADDR_INTR to aggregated Error MPU_ADDR_INTR_ERRAGG1'b1 : Error is Masked1'b0 : Error is Unmasked
  [5] MPU_ADDR_ERRAGG_R5SS0_CPU0_MASK_MPU_CR5B0_AXIS_ADDR_ERR0 — Mask Error from MPU_ADDR_INTR to aggregated Error MPU_ADDR_INTR_ERRAGG1'b1 : Error is Masked1'b0 : Error is Unmasked
  [4] MPU_ADDR_ERRAGG_R5SS0_CPU0_MASK_MPU_CR5A0_AXIS_ADDR_ERR0 — Mask Error from MPU_ADDR_INTR to aggregated Error MPU_ADDR_INTR_ERRAGG1'b1 : Error is Masked1'b0 : Error is Unmasked
  [3] MPU_ADDR_ERRAGG_R5SS0_CPU0_MASK_MPU_L2_BANK_D_ADDR_ERR0 — Mask Error from MPU_ADDR_INTR to aggregated Error MPU_ADDR_INTR_ERRAGG1'b1 : Error is Masked1'b0 : Error is Unmasked
  [2] MPU_ADDR_ERRAGG_R5SS0_CPU0_MASK_MPU_L2_BANK_C_ADDR_ERR0 — Mask Error from MPU_ADDR_INTR to aggregated Error MPU_ADDR_INTR_ERRAGG1'b1 : Error is Masked1'b0 : Error is Unmasked
  [1] MPU_ADDR_ERRAGG_R5SS0_CPU0_MASK_MPU_L2_BANK_B_ADDR_ERR0 — Mask Error from MPU_ADDR_INTR to aggregated Error MPU_ADDR_INTR_ERRAGG1'b1 : Error is Masked1'b0 : Error is Unmasked
  [0] MPU_ADDR_ERRAGG_R5SS0_CPU0_MASK_MPU_L2_BANK_A_ADDR_ERR0 — Mask Error from MPU_ADDR_INTR to aggregated Error MPU_ADDR_INTR_ERRAGG1'b1 : Error is Masked1'b0 : Error is Unmasked
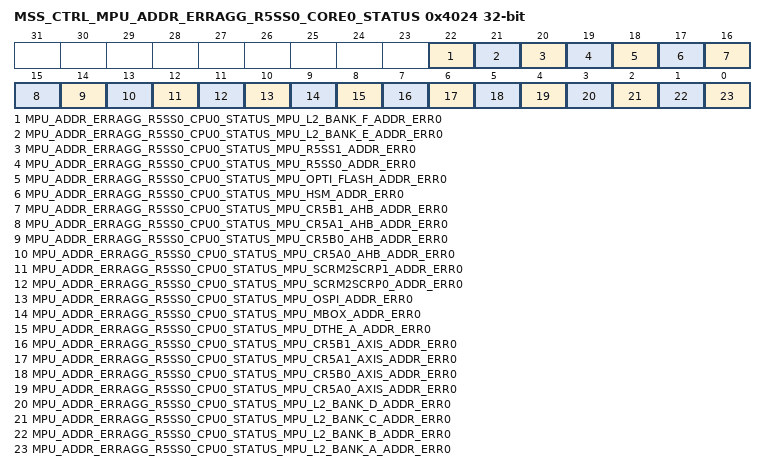
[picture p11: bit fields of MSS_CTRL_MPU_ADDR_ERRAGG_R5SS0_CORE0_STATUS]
0x4024 MSS_CTRL_MPU_ADDR_ERRAGG_R5SS0_CORE0_STATUS
  [22] MPU_ADDR_ERRAGG_R5SS0_CPU0_STATUS_MPU_L2_BANK_F_ADDR_ERR0 — Status of Error from MPU_ADDR_INTR. Set only if Interupt is unmasked in MPU_ADDR_INTR_ERRAGG_MASKWrie 0x1 to clear this Error.
  [21] MPU_ADDR_ERRAGG_R5SS0_CPU0_STATUS_MPU_L2_BANK_E_ADDR_ERR0 — Status of Error from MPU_ADDR_INTR. Set only if Interupt is unmasked in MPU_ADDR_INTR_ERRAGG_MASKWrie 0x1 to clear this Error.
  [20] MPU_ADDR_ERRAGG_R5SS0_CPU0_STATUS_MPU_R5SS1_ADDR_ERR0 — Status of Error from MPU_ADDR_INTR. Set only if Interupt is unmasked in MPU_ADDR_INTR_ERRAGG_MASKWrie 0x1 to clear this Error.
  [19] MPU_ADDR_ERRAGG_R5SS0_CPU0_STATUS_MPU_R5SS0_ADDR_ERR0 — Status of Error from MPU_ADDR_INTR. Set only if Interupt is unmasked in MPU_ADDR_INTR_ERRAGG_MASKWrie 0x1 to clear this Error.
  [18] MPU_ADDR_ERRAGG_R5SS0_CPU0_STATUS_MPU_OPTI_FLASH_ADDR_ERR0 — Status of Error from MPU_ADDR_INTR. Set only if Interupt is unmasked in MPU_ADDR_INTR_ERRAGG_MASKWrie 0x1 to clear this Error.
  [17] MPU_ADDR_ERRAGG_R5SS0_CPU0_STATUS_MPU_HSM_ADDR_ERR0 — Status of Error from MPU_ADDR_INTR. Set only if Interupt is unmasked in MPU_ADDR_INTR_ERRAGG_MASKWrie 0x1 to clear this Error.
  [16] MPU_ADDR_ERRAGG_R5SS0_CPU0_STATUS_MPU_CR5B1_AHB_ADDR_ERR0 — Status of Error from MPU_ADDR_INTR. Set only if Interupt is unmasked in MPU_ADDR_INTR_ERRAGG_MASKWrie 0x1 to clear this Error.
  [15] MPU_ADDR_ERRAGG_R5SS0_CPU0_STATUS_MPU_CR5A1_AHB_ADDR_ERR0 — Status of Error from MPU_ADDR_INTR. Set only if Interupt is unmasked in MPU_ADDR_INTR_ERRAGG_MASKWrie 0x1 to clear this Error.
  [14] MPU_ADDR_ERRAGG_R5SS0_CPU0_STATUS_MPU_CR5B0_AHB_ADDR_ERR0 — Status of Error from MPU_ADDR_INTR. Set only if Interupt is unmasked in MPU_ADDR_INTR_ERRAGG_MASKWrie 0x1 to clear this Error.
  [13] MPU_ADDR_ERRAGG_R5SS0_CPU0_STATUS_MPU_CR5A0_AHB_ADDR_ERR0 — Status of Error from MPU_ADDR_INTR. Set only if Interupt is unmasked in MPU_ADDR_INTR_ERRAGG_MASKWrie 0x1 to clear this Error.
  [12] MPU_ADDR_ERRAGG_R5SS0_CPU0_STATUS_MPU_SCRM2SCRP1_ADDR_ERR0 — Status of Error from MPU_ADDR_INTR. Set only if Interupt is unmasked in MPU_ADDR_INTR_ERRAGG_MASKWrie 0x1 to clear this Error.
  [11] MPU_ADDR_ERRAGG_R5SS0_CPU0_STATUS_MPU_SCRM2SCRP0_ADDR_ERR0 — Status of Error from MPU_ADDR_INTR. Set only if Interupt is unmasked in MPU_ADDR_INTR_ERRAGG_MASKWrie 0x1 to clear this Error.
  [10] MPU_ADDR_ERRAGG_R5SS0_CPU0_STATUS_MPU_OSPI_ADDR_ERR0 — Status of Error from MPU_ADDR_INTR. Set only if Interupt is unmasked in MPU_ADDR_INTR_ERRAGG_MASKWrie 0x1 to clear this Error.
  [9] MPU_ADDR_ERRAGG_R5SS0_CPU0_STATUS_MPU_MBOX_ADDR_ERR0 — Status of Error from MPU_ADDR_INTR. Set only if Interupt is unmasked in MPU_ADDR_INTR_ERRAGG_MASKWrie 0x1 to clear this Error.
  [8] MPU_ADDR_ERRAGG_R5SS0_CPU0_STATUS_MPU_DTHE_A_ADDR_ERR0 — Status of Error from MPU_ADDR_INTR. Set only if Interupt is unmasked in MPU_ADDR_INTR_ERRAGG_MASKWrie 0x1 to clear this Error.
  [7] MPU_ADDR_ERRAGG_R5SS0_CPU0_STATUS_MPU_CR5B1_AXIS_ADDR_ERR0 — Status of Error from MPU_ADDR_INTR. Set only if Interupt is unmasked in MPU_ADDR_INTR_ERRAGG_MASKWrie 0x1 to clear this Error.
  [6] MPU_ADDR_ERRAGG_R5SS0_CPU0_STATUS_MPU_CR5A1_AXIS_ADDR_ERR0 — Status of Error from MPU_ADDR_INTR. Set only if Interupt is unmasked in MPU_ADDR_INTR_ERRAGG_MASKWrie 0x1 to clear this Error.
  [5] MPU_ADDR_ERRAGG_R5SS0_CPU0_STATUS_MPU_CR5B0_AXIS_ADDR_ERR0 — Status of Error from MPU_ADDR_INTR. Set only if Interupt is unmasked in MPU_ADDR_INTR_ERRAGG_MASKWrie 0x1 to clear this Error.
  [4] MPU_ADDR_ERRAGG_R5SS0_CPU0_STATUS_MPU_CR5A0_AXIS_ADDR_ERR0 — Status of Error from MPU_ADDR_INTR. Set only if Interupt is unmasked in MPU_ADDR_INTR_ERRAGG_MASKWrie 0x1 to clear this Error.
  [3] MPU_ADDR_ERRAGG_R5SS0_CPU0_STATUS_MPU_L2_BANK_D_ADDR_ERR0 — Status of Error from MPU_ADDR_INTR. Set only if Interupt is unmasked in MPU_ADDR_INTR_ERRAGG_MASKWrie 0x1 to clear this Error.
  [2] MPU_ADDR_ERRAGG_R5SS0_CPU0_STATUS_MPU_L2_BANK_C_ADDR_ERR0 — Status of Error from MPU_ADDR_INTR. Set only if Interupt is unmasked in MPU_ADDR_INTR_ERRAGG_MASKWrie 0x1 to clear this Error.
  [1] MPU_ADDR_ERRAGG_R5SS0_CPU0_STATUS_MPU_L2_BANK_B_ADDR_ERR0 — Status of Error from MPU_ADDR_INTR. Set only if Interupt is unmasked in MPU_ADDR_INTR_ERRAGG_MASKWrie 0x1 to clear this Error.
  [0] MPU_ADDR_ERRAGG_R5SS0_CPU0_STATUS_MPU_L2_BANK_A_ADDR_ERR0 — Status of Error from MPU_ADDR_INTR. Set only if Interupt is unmasked in MPU_ADDR_INTR_ERRAGG_MASKWrie 0x1 to clear this Error.
